VERSION "created by canmatrix"

NS_ :

BS_:

BU_:

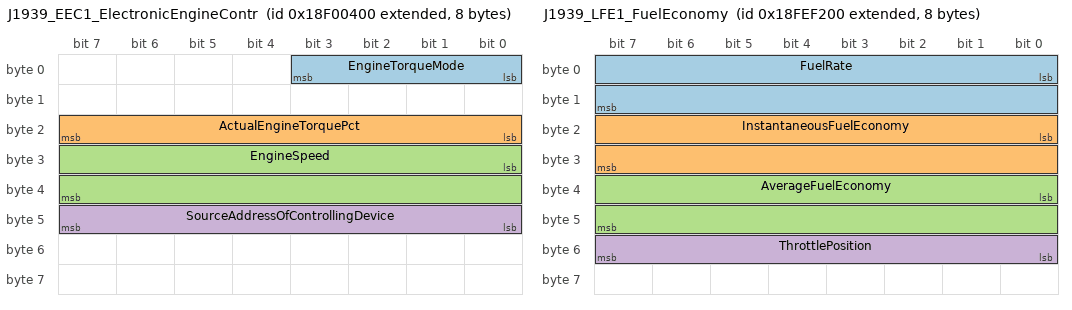
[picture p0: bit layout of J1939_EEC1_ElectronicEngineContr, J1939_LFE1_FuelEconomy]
BO_ 2565866496 J1939_EEC1_ElectronicEngineContr: 8 Vector__XXX
 SG_ EngineTorqueMode : 0|4@1+ (1,0) [0|15] "" Vector__XXX
 SG_ ActualEngineTorquePct : 16|8@1+ (1,-125) [-125|130] "%" Vector__XXX
 SG_ EngineSpeed : 24|16@1+ (0.125,0) [0|8191.875] "rpm" Vector__XXX
 SG_ SourceAddressOfControllingDevice : 40|8@1+ (1,0) [0|255] "" Vector__XXX

BO_ 2566844928 J1939_LFE1_FuelEconomy: 8 Vector__XXX
 SG_ FuelRate : 0|16@1+ (0.05,0) [0|3276.75] "L/h" Vector__XXX
 SG_ InstantaneousFuelEconomy : 16|16@1+ (0.001953,0) [0|127.989855] "km/L" Vector__XXX
 SG_ AverageFuelEconomy : 32|16@1+ (0.001953,0) [0|127.989855] "km/L" Vector__XXX
 SG_ ThrottlePosition : 48|8@1+ (0.4,0) [0|102] "%" Vector__XXX

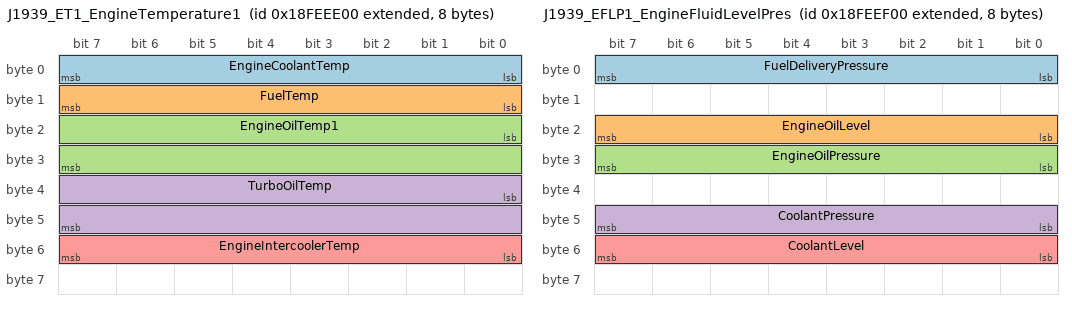
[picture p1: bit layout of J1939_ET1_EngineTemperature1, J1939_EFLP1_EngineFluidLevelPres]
BO_ 2566843904 J1939_ET1_EngineTemperature1: 8 Vector__XXX
 SG_ EngineCoolantTemp : 0|8@1+ (1,-40) [-40|215] "°C" Vector__XXX
 SG_ FuelTemp : 8|8@1+ (1,-40) [-40|215] "°C" Vector__XXX
 SG_ EngineOilTemp1 : 16|16@1+ (0.03125,-273) [-273|1774.96875] "°C" Vector__XXX
 SG_ TurboOilTemp : 32|16@1+ (0.03125,-273) [-273|1774.96875] "°C" Vector__XXX
 SG_ EngineIntercoolerTemp : 48|8@1+ (1,-40) [-40|215] "°C" Vector__XXX

BO_ 2566844160 J1939_EFLP1_EngineFluidLevelPres: 8 Vector__XXX
 SG_ FuelDeliveryPressure : 0|8@1+ (4,0) [0|1020] "kPa" Vector__XXX
 SG_ EngineOilLevel : 16|8@1+ (0.4,0) [0|102] "%" Vector__XXX
 SG_ EngineOilPressure : 24|8@1+ (4,0) [0|1020] "kPa" Vector__XXX
 SG_ CoolantPressure : 40|8@1+ (2,0) [0|510] "kPa" Vector__XXX
 SG_ CoolantLevel : 48|8@1+ (0.4,0) [0|102] "%" Vector__XXX

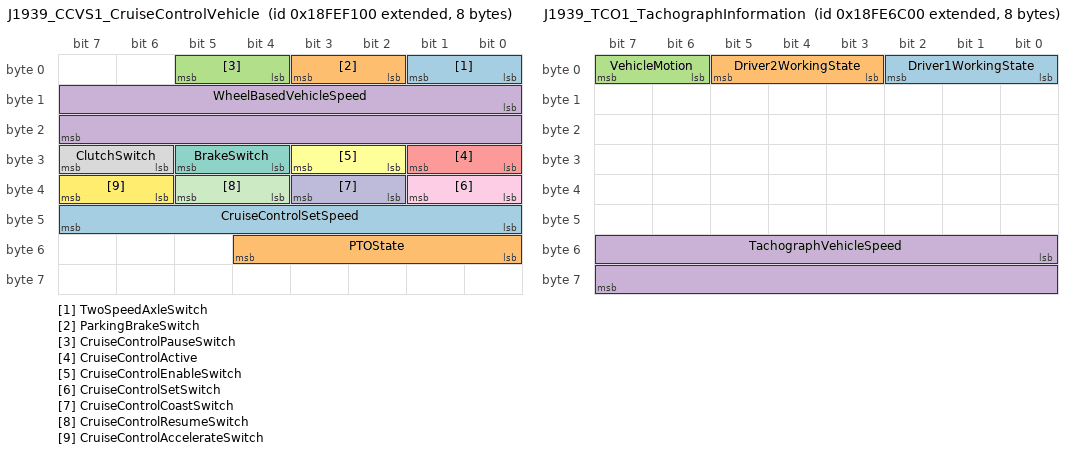
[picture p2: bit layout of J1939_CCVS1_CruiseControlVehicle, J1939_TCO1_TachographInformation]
BO_ 2566844672 J1939_CCVS1_CruiseControlVehicle: 8 Vector__XXX
 SG_ TwoSpeedAxleSwitch : 0|2@1+ (1,0) [0|3] "" Vector__XXX
 SG_ ParkingBrakeSwitch : 2|2@1+ (1,0) [0|3] "" Vector__XXX
 SG_ CruiseControlPauseSwitch : 4|2@1+ (1,0) [0|3] "" Vector__XXX
 SG_ WheelBasedVehicleSpeed : 8|16@1+ (0.003906,0) [0|255.97971] "km/h" Vector__XXX
 SG_ CruiseControlActive : 24|2@1+ (1,0) [0|3] "" Vector__XXX
 SG_ CruiseControlEnableSwitch : 26|2@1+ (1,0) [0|3] "" Vector__XXX
 SG_ BrakeSwitch : 28|2@1+ (1,0) [0|3] "" Vector__XXX
 SG_ ClutchSwitch : 30|2@1+ (1,0) [0|3] "" Vector__XXX
 SG_ CruiseControlSetSwitch : 32|2@1+ (1,0) [0|3] "" Vector__XXX
 SG_ CruiseControlCoastSwitch : 34|2@1+ (1,0) [0|3] "" Vector__XXX
 SG_ CruiseControlResumeSwitch : 36|2@1+ (1,0) [0|3] "" Vector__XXX
 SG_ CruiseControlAccelerateSwitch : 38|2@1+ (1,0) [0|3] "" Vector__XXX
 SG_ CruiseControlSetSpeed : 40|8@1+ (1,0) [0|255] "km/h" Vector__XXX
 SG_ PTOState : 48|5@1+ (1,0) [0|31] "" Vector__XXX

BO_ 2566810624 J1939_TCO1_TachographInformation: 8 Vector__XXX
 SG_ Driver1WorkingState : 0|3@1+ (1,0) [0|7] "" Vector__XXX
 SG_ Driver2WorkingState : 3|3@1+ (1,0) [0|7] "" Vector__XXX
 SG_ VehicleMotion : 6|2@1+ (1,0) [0|3] "" Vector__XXX
 SG_ TachographVehicleSpeed : 48|16@1+ (0.003906,0) [0|255.97971] "km/h" Vector__XXX

BO_ 2566841600 J1939_HOURS_EngineHours: 8 Vector__XXX
 SG_ EngineTotalHoursOfOperation : 0|32@1+ (0.05,0) [0|214748364.75] "h" Vector__XXX
 SG_ EngineTotalRevolutions : 32|32@1+ (1000,0) [0|4294967295000] "r" Vector__XXX

BO_ 2566843392 J1939_VI_VehicleIdentification: 8 Vector__XXX
 SG_ VIN_Char01 : 0|8@1+ (1,0) [0|255] "" Vector__XXX

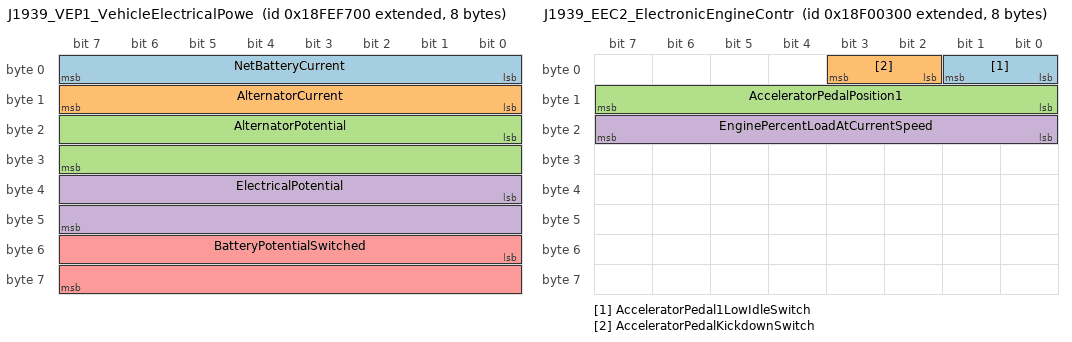
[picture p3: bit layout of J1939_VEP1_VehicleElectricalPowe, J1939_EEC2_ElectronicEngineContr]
BO_ 2566846208 J1939_VEP1_VehicleElectricalPowe: 8 Vector__XXX
 SG_ NetBatteryCurrent : 0|8@1+ (1,-125) [-125|130] "A" Vector__XXX
 SG_ AlternatorCurrent : 8|8@1+ (1,0) [0|255] "A" Vector__XXX
 SG_ AlternatorPotential : 16|16@1+ (0.05,0) [0|3276.75] "V" Vector__XXX
 SG_ ElectricalPotential : 32|16@1+ (0.05,0) [0|3276.75] "V" Vector__XXX
 SG_ BatteryPotentialSwitched : 48|16@1+ (0.05,0) [0|3276.75] "V" Vector__XXX

BO_ 2566749184 J1939_DEF_DieselExhaustFluidConc: 8 Vector__XXX
 SG_ DEFTankLevel : 0|8@1+ (0.4,0) [0|102] "%" Vector__XXX
 SG_ DEFTankTemperature : 8|8@1+ (1,-40) [-40|215] "°C" Vector__XXX

BO_ 2566841088 J1939_EC1_EngineConfiguration1: 8 Vector__XXX
 SG_ EngineSpeedAtIdle : 0|16@1+ (0.125,0) [0|8191.875] "rpm" Vector__XXX
 SG_ EngineSpeedAtMaxIdlePoint1 : 24|16@1+ (0.125,0) [0|8191.875] "rpm" Vector__XXX

BO_ 2566840064 J1939_EEC3_ElectronicEngineContr: 8 Vector__XXX
 SG_ EngineDemandPercentTorque : 56|8@1+ (1,-125) [-125|130] "%" Vector__XXX

BO_ 2565866240 J1939_EEC2_ElectronicEngineContr: 8 Vector__XXX
 SG_ AcceleratorPedal1LowIdleSwitch : 0|2@1+ (1,0) [0|3] "" Vector__XXX
 SG_ AcceleratorPedalKickdownSwitch : 2|2@1+ (1,0) [0|3] "" Vector__XXX
 SG_ AcceleratorPedalPosition1 : 8|8@1+ (0.4,0) [0|102] "%" Vector__XXX
 SG_ EnginePercentLoadAtCurrentSpeed : 16|8@1+ (1,0) [0|255] "%" Vector__XXX

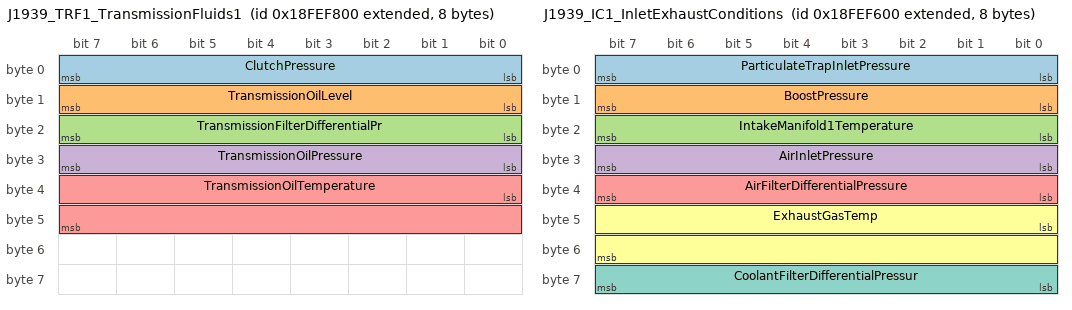
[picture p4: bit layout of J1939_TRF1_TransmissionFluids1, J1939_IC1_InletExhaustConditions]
BO_ 2566846464 J1939_TRF1_TransmissionFluids1: 8 Vector__XXX
 SG_ ClutchPressure : 0|8@1+ (16,0) [0|4080] "kPa" Vector__XXX
 SG_ TransmissionOilLevel : 8|8@1+ (0.4,0) [0|102] "%" Vector__XXX
 SG_ TransmissionFilterDifferentialPr : 16|8@1+ (2,0) [0|510] "kPa" Vector__XXX
 SG_ TransmissionOilPressure : 24|8@1+ (16,0) [0|4080] "kPa" Vector__XXX
 SG_ TransmissionOilTemperature : 32|16@1+ (0.03125,-273) [-273|1774.96875] "°C" Vector__XXX

BO_ 2566845952 J1939_IC1_InletExhaustConditions: 8 Vector__XXX
 SG_ ParticulateTrapInletPressure : 0|8@1+ (0.5,0) [0|127.5] "kPa" Vector__XXX
 SG_ BoostPressure : 8|8@1+ (2,0) [0|510] "kPa" Vector__XXX
 SG_ IntakeManifold1Temperature : 16|8@1+ (1,-40) [-40|215] "°C" Vector__XXX
 SG_ AirInletPressure : 24|8@1+ (2,0) [0|510] "kPa" Vector__XXX
 SG_ AirFilterDifferentialPressure : 32|8@1+ (0.05,0) [0|12.75] "kPa" Vector__XXX
 SG_ ExhaustGasTemp : 40|16@1+ (0.03125,-273) [-273|1774.96875] "°C" Vector__XXX
 SG_ CoolantFilterDifferentialPressur : 56|8@1+ (0.5,0) [0|127.5] "kPa" Vector__XXX

BO_ 2566697472 J1939_FFE_FuelEconomyExtended: 8 Vector__XXX
 SG_ EngineTripFuel : 0|32@1+ (0.5,0) [0|2147483647.5] "L" Vector__XXX
 SG_ EngineTotalFuelUsed : 32|32@1+ (0.5,0) [0|2147483647.5] "L" Vector__XXX

BO_ 2566832384 J1939_HRVD_HighResolutionVehicle: 8 Vector__XXX
 SG_ HighResolutionTotalVehicleDistan : 0|32@1+ (5,0) [0|21474836475] "m" Vector__XXX
 SG_ HighResolutionTripDistance : 32|32@1+ (5,0) [0|21474836475] "m" Vector__XXX

CM_ BO_ 2565866496  "Engine speed, torque mode, demand torque. Source: Wikipedia SAE J1939 PGN list (en.wikipedia.org/wiki/SAE_J1939)";
CM_ BO_ 2566844928  "Fuel rate + instantaneous + average fuel economy. Source: Wikipedia SAE J1939 PGN list (en.wikipedia.org/wiki/SAE_J1939)";
CM_ BO_ 2566843904  "Coolant + fuel + engine oil + intercooler temperatures. Source: Wikipedia SAE J1939 PGN list (en.wikipedia.org/wiki/SAE_J1939)";
CM_ BO_ 2566844160  "Oil pressure/level + coolant pressure/level + fuel delivery pressure. Source: Wikipedia SAE J1939 PGN list (en.wikipedia.org/wiki/SAE_J1939)";
CM_ BO_ 2566844672  "Vehicle speed + cruise control state + brake/clutch/parking switches. Source: Wikipedia SAE J1939 PGN list (en.wikipedia.org/wiki/SAE_J1939)";
CM_ BO_ 2566810624  "Tachograph + driver state (mostly for heavy-truck FMS). Source: Wikipedia SAE J1939 PGN list (en.wikipedia.org/wiki/SAE_J1939)";
CM_ BO_ 2566841600  "Engine total hours of operation. Source: Wikipedia SAE J1939 PGN list (en.wikipedia.org/wiki/SAE_J1939)";
CM_ BO_ 2566843392  "Vehicle Identification Number (VIN). Source: Wikipedia SAE J1939 PGN list (en.wikipedia.org/wiki/SAE_J1939)";
CM_ BO_ 2566846208  "Battery + alternator + engine starter electrical state. Source: Wikipedia SAE J1939 PGN list (en.wikipedia.org/wiki/SAE_J1939)";
CM_ BO_ 2566749184  "DEF (urea) tank level + temperature + concentration. Source: Wikipedia SAE J1939 PGN list (en.wikipedia.org/wiki/SAE_J1939)";
CM_ BO_ 2566841088  "Engine configuration data — displacement, speed limits, fuel type. Source: Wikipedia SAE J1939 PGN list (en.wikipedia.org/wiki/SAE_J1939)";
CM_ BO_ 2566840064  "Engine demand percent torque + nominal friction torque. Source: Wikipedia SAE J1939 PGN list (en.wikipedia.org/wiki/SAE_J1939)";
CM_ BO_ 2565866240  "Accelerator pedal + percent load. Source: Wikipedia SAE J1939 PGN list (en.wikipedia.org/wiki/SAE_J1939)";
CM_ BO_ 2566846464  "Transmission oil + clutch pressure. Source: Wikipedia SAE J1939 PGN list (en.wikipedia.org/wiki/SAE_J1939)";
CM_ BO_ 2566845952  "Boost + intake air temp + air filter differential pressure. Source: Wikipedia SAE J1939 PGN list (en.wikipedia.org/wiki/SAE_J1939)";
CM_ BO_ 2566697472  "Trip fuel + total fuel + trip distance. Source: Wikipedia SAE J1939 PGN list (en.wikipedia.org/wiki/SAE_J1939)";
CM_ BO_ 2566832384  "High-resolution vehicle distance (HRVD per SAE J1939-71). Source: Wikipedia SAE J1939 PGN list (en.wikipedia.org/wiki/SAE_J1939)";

CM_ SG_ 2565866496 EngineTorqueMode "Per-signal source: Wikipedia SAE J1939 PGN list (en.wikipedia.org/wiki/SAE_J1939)";
CM_ SG_ 2565866496 ActualEngineTorquePct "Actual engine percent torque";
CM_ SG_ 2565866496 EngineSpeed "Per-signal source: Wikipedia SAE J1939 PGN list (en.wikipedia.org/wiki/SAE_J1939)";
CM_ SG_ 2565866496 SourceAddressOfControllingDevice "Source address of the device commanding engine torque";
CM_ SG_ 2566844928 FuelRate "Per-signal source: Wikipedia SAE J1939 PGN list (en.wikipedia.org/wiki/SAE_J1939)";
CM_ SG_ 2566844928 InstantaneousFuelEconomy "Per-signal source: Wikipedia SAE J1939 PGN list (en.wikipedia.org/wiki/SAE_J1939)";
CM_ SG_ 2566844928 AverageFuelEconomy "Per-signal source: Wikipedia SAE J1939 PGN list (en.wikipedia.org/wiki/SAE_J1939)";
CM_ SG_ 2566844928 ThrottlePosition "Per-signal source: Wikipedia SAE J1939 PGN list (en.wikipedia.org/wiki/SAE_J1939)";
CM_ SG_ 2566843904 EngineCoolantTemp "Per-signal source: Wikipedia SAE J1939 PGN list (en.wikipedia.org/wiki/SAE_J1939)";
CM_ SG_ 2566843904 FuelTemp "Per-signal source: Wikipedia SAE J1939 PGN list (en.wikipedia.org/wiki/SAE_J1939)";
CM_ SG_ 2566843904 EngineOilTemp1 "Per-signal source: Wikipedia SAE J1939 PGN list (en.wikipedia.org/wiki/SAE_J1939)";
CM_ SG_ 2566843904 TurboOilTemp "Per-signal source: Wikipedia SAE J1939 PGN list (en.wikipedia.org/wiki/SAE_J1939)";
CM_ SG_ 2566843904 EngineIntercoolerTemp "Per-signal source: Wikipedia SAE J1939 PGN list (en.wikipedia.org/wiki/SAE_J1939)";
CM_ SG_ 2566844160 FuelDeliveryPressure "Per-signal source: Wikipedia SAE J1939 PGN list (en.wikipedia.org/wiki/SAE_J1939)";
CM_ SG_ 2566844160 EngineOilLevel "Per-signal source: Wikipedia SAE J1939 PGN list (en.wikipedia.org/wiki/SAE_J1939)";
CM_ SG_ 2566844160 EngineOilPressure "Per-signal source: Wikipedia SAE J1939 PGN list (en.wikipedia.org/wiki/SAE_J1939)";
CM_ SG_ 2566844160 CoolantPressure "Per-signal source: Wikipedia SAE J1939 PGN list (en.wikipedia.org/wiki/SAE_J1939)";
CM_ SG_ 2566844160 CoolantLevel "Per-signal source: Wikipedia SAE J1939 PGN list (en.wikipedia.org/wiki/SAE_J1939)";
CM_ SG_ 2566844672 TwoSpeedAxleSwitch "Per-signal source: Wikipedia SAE J1939 PGN list (en.wikipedia.org/wiki/SAE_J1939)";
CM_ SG_ 2566844672 ParkingBrakeSwitch "Per-signal source: Wikipedia SAE J1939 PGN list (en.wikipedia.org/wiki/SAE_J1939)";
CM_ SG_ 2566844672 CruiseControlPauseSwitch "Per-signal source: Wikipedia SAE J1939 PGN list (en.wikipedia.org/wiki/SAE_J1939)";
CM_ SG_ 2566844672 WheelBasedVehicleSpeed "Per-signal source: Wikipedia SAE J1939 PGN list (en.wikipedia.org/wiki/SAE_J1939)";
CM_ SG_ 2566844672 CruiseControlActive "Per-signal source: Wikipedia SAE J1939 PGN list (en.wikipedia.org/wiki/SAE_J1939)";
CM_ SG_ 2566844672 CruiseControlEnableSwitch "Per-signal source: Wikipedia SAE J1939 PGN list (en.wikipedia.org/wiki/SAE_J1939)";
CM_ SG_ 2566844672 BrakeSwitch "Per-signal source: Wikipedia SAE J1939 PGN list (en.wikipedia.org/wiki/SAE_J1939)";
CM_ SG_ 2566844672 ClutchSwitch "Per-signal source: Wikipedia SAE J1939 PGN list (en.wikipedia.org/wiki/SAE_J1939)";
CM_ SG_ 2566844672 CruiseControlSetSwitch "Per-signal source: Wikipedia SAE J1939 PGN list (en.wikipedia.org/wiki/SAE_J1939)";
CM_ SG_ 2566844672 CruiseControlCoastSwitch "Per-signal source: Wikipedia SAE J1939 PGN list (en.wikipedia.org/wiki/SAE_J1939)";
CM_ SG_ 2566844672 CruiseControlResumeSwitch "Per-signal source: Wikipedia SAE J1939 PGN list (en.wikipedia.org/wiki/SAE_J1939)";
CM_ SG_ 2566844672 CruiseControlAccelerateSwitch "Per-signal source: Wikipedia SAE J1939 PGN list (en.wikipedia.org/wiki/SAE_J1939)";
CM_ SG_ 2566844672 CruiseControlSetSpeed "Per-signal source: Wikipedia SAE J1939 PGN list (en.wikipedia.org/wiki/SAE_J1939)";
CM_ SG_ 2566844672 PTOState "Per-signal source: Wikipedia SAE J1939 PGN list (en.wikipedia.org/wiki/SAE_J1939)";
CM_ SG_ 2566810624 Driver1WorkingState "Per-signal source: Wikipedia SAE J1939 PGN list (en.wikipedia.org/wiki/SAE_J1939)";
CM_ SG_ 2566810624 Driver2WorkingState "Per-signal source: Wikipedia SAE J1939 PGN list (en.wikipedia.org/wiki/SAE_J1939)";
CM_ SG_ 2566810624 VehicleMotion "Per-signal source: Wikipedia SAE J1939 PGN list (en.wikipedia.org/wiki/SAE_J1939)";
CM_ SG_ 2566810624 TachographVehicleSpeed "Per-signal source: Wikipedia SAE J1939 PGN list (en.wikipedia.org/wiki/SAE_J1939)";
CM_ SG_ 2566841600 EngineTotalHoursOfOperation "Per-signal source: Wikipedia SAE J1939 PGN list (en.wikipedia.org/wiki/SAE_J1939)";
CM_ SG_ 2566841600 EngineTotalRevolutions "Per-signal source: Wikipedia SAE J1939 PGN list (en.wikipedia.org/wiki/SAE_J1939)";
CM_ SG_ 2566843392 VIN_Char01 "ASCII byte 0 of VIN; full VIN spans multipacket";
CM_ SG_ 2566846208 NetBatteryCurrent "Per-signal source: Wikipedia SAE J1939 PGN list (en.wikipedia.org/wiki/SAE_J1939)";
CM_ SG_ 2566846208 AlternatorCurrent "Per-signal source: Wikipedia SAE J1939 PGN list (en.wikipedia.org/wiki/SAE_J1939)";
CM_ SG_ 2566846208 AlternatorPotential "Per-signal source: Wikipedia SAE J1939 PGN list (en.wikipedia.org/wiki/SAE_J1939)";
CM_ SG_ 2566846208 ElectricalPotential "Per-signal source: Wikipedia SAE J1939 PGN list (en.wikipedia.org/wiki/SAE_J1939)";
CM_ SG_ 2566846208 BatteryPotentialSwitched "Per-signal source: Wikipedia SAE J1939 PGN list (en.wikipedia.org/wiki/SAE_J1939)";
CM_ SG_ 2566749184 DEFTankLevel "Per-signal source: Wikipedia SAE J1939 PGN list (en.wikipedia.org/wiki/SAE_J1939)";
CM_ SG_ 2566749184 DEFTankTemperature "Per-signal source: Wikipedia SAE J1939 PGN list (en.wikipedia.org/wiki/SAE_J1939)";
CM_ SG_ 2566841088 EngineSpeedAtIdle "Per-signal source: Wikipedia SAE J1939 PGN list (en.wikipedia.org/wiki/SAE_J1939)";
CM_ SG_ 2566841088 EngineSpeedAtMaxIdlePoint1 "Per-signal source: Wikipedia SAE J1939 PGN list (en.wikipedia.org/wiki/SAE_J1939)";
CM_ SG_ 2566840064 EngineDemandPercentTorque "Per-signal source: Wikipedia SAE J1939 PGN list (en.wikipedia.org/wiki/SAE_J1939)";
CM_ SG_ 2565866240 AcceleratorPedal1LowIdleSwitch "Per-signal source: Wikipedia SAE J1939 PGN list (en.wikipedia.org/wiki/SAE_J1939)";
CM_ SG_ 2565866240 AcceleratorPedalKickdownSwitch "Per-signal source: Wikipedia SAE J1939 PGN list (en.wikipedia.org/wiki/SAE_J1939)";
CM_ SG_ 2565866240 AcceleratorPedalPosition1 "Per-signal source: Wikipedia SAE J1939 PGN list (en.wikipedia.org/wiki/SAE_J1939)";
CM_ SG_ 2565866240 EnginePercentLoadAtCurrentSpeed "Per-signal source: Wikipedia SAE J1939 PGN list (en.wikipedia.org/wiki/SAE_J1939)";
CM_ SG_ 2566846464 ClutchPressure "Per-signal source: Wikipedia SAE J1939 PGN list (en.wikipedia.org/wiki/SAE_J1939)";
CM_ SG_ 2566846464 TransmissionOilLevel "Per-signal source: Wikipedia SAE J1939 PGN list (en.wikipedia.org/wiki/SAE_J1939)";
CM_ SG_ 2566846464 TransmissionFilterDifferentialPr "Per-signal source: Wikipedia SAE J1939 PGN list (en.wikipedia.org/wiki/SAE_J1939)";
CM_ SG_ 2566846464 TransmissionOilPressure "Per-signal source: Wikipedia SAE J1939 PGN list (en.wikipedia.org/wiki/SAE_J1939)";
CM_ SG_ 2566846464 TransmissionOilTemperature "Per-signal source: Wikipedia SAE J1939 PGN list (en.wikipedia.org/wiki/SAE_J1939)";
CM_ SG_ 2566845952 ParticulateTrapInletPressure "Per-signal source: Wikipedia SAE J1939 PGN list (en.wikipedia.org/wiki/SAE_J1939)";
CM_ SG_ 2566845952 BoostPressure "Per-signal source: Wikipedia SAE J1939 PGN list (en.wikipedia.org/wiki/SAE_J1939)";
CM_ SG_ 2566845952 IntakeManifold1Temperature "Per-signal source: Wikipedia SAE J1939 PGN list (en.wikipedia.org/wiki/SAE_J1939)";
CM_ SG_ 2566845952 AirInletPressure "Per-signal source: Wikipedia SAE J1939 PGN list (en.wikipedia.org/wiki/SAE_J1939)";
CM_ SG_ 2566845952 AirFilterDifferentialPressure "Per-signal source: Wikipedia SAE J1939 PGN list (en.wikipedia.org/wiki/SAE_J1939)";
CM_ SG_ 2566845952 ExhaustGasTemp "Per-signal source: Wikipedia SAE J1939 PGN list (en.wikipedia.org/wiki/SAE_J1939)";
CM_ SG_ 2566845952 CoolantFilterDifferentialPressur "Per-signal source: Wikipedia SAE J1939 PGN list (en.wikipedia.org/wiki/SAE_J1939)";
CM_ SG_ 2566697472 EngineTripFuel "Per-signal source: Wikipedia SAE J1939 PGN list (en.wikipedia.org/wiki/SAE_J1939)";
CM_ SG_ 2566697472 EngineTotalFuelUsed "Per-signal source: Wikipedia SAE J1939 PGN list (en.wikipedia.org/wiki/SAE_J1939)";
CM_ SG_ 2566832384 HighResolutionTotalVehicleDistan "Per-signal source: Wikipedia SAE J1939 PGN list (en.wikipedia.org/wiki/SAE_J1939)";
CM_ SG_ 2566832384 HighResolutionTripDistance "Per-signal source: Wikipedia SAE J1939 PGN list (en.wikipedia.org/wiki/SAE_J1939)";

BA_DEF_ BO_ "SystemMessageLongSymbol" STRING;
BA_DEF_ SG_ "GenSigStartValue" FLOAT 0 100000000000;
BA_DEF_ SG_ "SystemSignalLongSymbol" STRING;

BA_ "SystemMessageLongSymbol" BO_ 2565866496 "J1939_EEC1_ElectronicEngineController1";
BA_ "SystemMessageLongSymbol" BO_ 2566844160 "J1939_EFLP1_EngineFluidLevelPressure1";
BA_ "SystemMessageLongSymbol" BO_ 2566844672 "J1939_CCVS1_CruiseControlVehicleSpeed1";
BA_ "SystemMessageLongSymbol" BO_ 2566846208 "J1939_VEP1_VehicleElectricalPower1";
BA_ "SystemMessageLongSymbol" BO_ 2566749184 "J1939_DEF_DieselExhaustFluidConcentration";
BA_ "SystemMessageLongSymbol" BO_ 2566840064 "J1939_EEC3_ElectronicEngineController3";
BA_ "SystemMessageLongSymbol" BO_ 2565866240 "J1939_EEC2_ElectronicEngineController2";
BA_ "SystemMessageLongSymbol" BO_ 2566845952 "J1939_IC1_InletExhaustConditions1";
BA_ "SystemMessageLongSymbol" BO_ 2566832384 "J1939_HRVD_HighResolutionVehicleDistance";

BA_ "SystemSignalLongSymbol" SG_ 2147548920 TransmissionFilterDifferentialPr "TransmissionFilterDifferentialPressure";
BA_ "SystemSignalLongSymbol" SG_ 2147548918 CoolantFilterDifferentialPressur "CoolantFilterDifferentialPressure";
BA_ "SystemSignalLongSymbol" SG_ 2147548865 HighResolutionTotalVehicleDistan "HighResolutionTotalVehicleDistance";

VAL_ 2565866496 EngineTorqueMode 0 "LowIdleGovernor" 1 "AcceleratorPedal" 2 "CruiseControl" 3 "PTOGovernor" 4 "RoadSpeedGovernor" 5 "ASRControl" 6 "TransmissionControl" 7 "ABSControl" 8 "TorqueLimiting" 9 "HighSpeedGovernor" 10 "BrakingSystem" 11 "RemoteAccelerator" 14 "Other" 15 "NotAvailable";

VERSION "created by canmatrix"

NS_ :

BS_:

BU_:

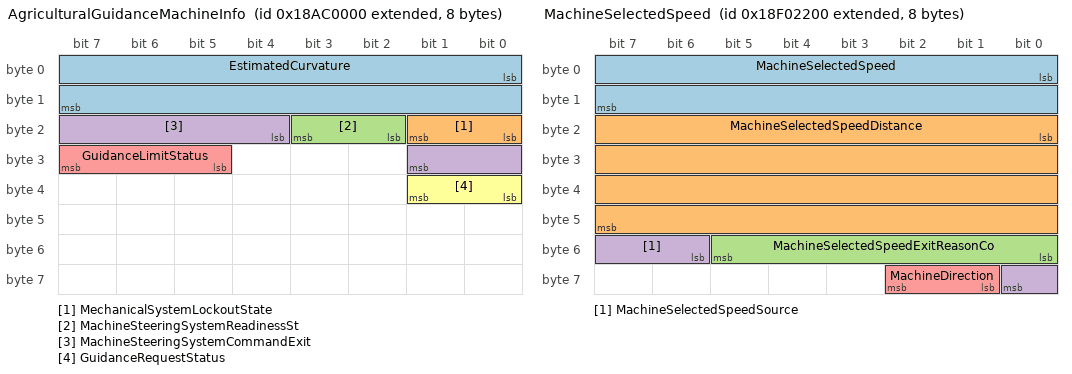
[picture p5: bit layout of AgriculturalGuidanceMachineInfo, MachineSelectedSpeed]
BO_ 2561409024 AgriculturalGuidanceMachineInfo: 8 Vector__XXX
 SG_ EstimatedCurvature : 0|16@1+ (0.25,-8032) [-8032|8351.75] "1/km" Vector__XXX
 SG_ MechanicalSystemLockoutState : 16|2@1+ (1,0) [0|3] "" Vector__XXX
 SG_ MachineSteeringSystemReadinessSt : 18|2@1+ (1,0) [0|3] "" Vector__XXX
 SG_ MachineSteeringSystemCommandExit : 20|6@1+ (1,0) [0|63] "" Vector__XXX
 SG_ GuidanceLimitStatus : 29|3@1+ (1,0) [0|7] "" Vector__XXX
 SG_ GuidanceRequestStatus : 32|2@1+ (1,0) [0|3] "" Vector__XXX

BO_ 2561474560 AgriculturalGuidanceSystemComman: 8 Vector__XXX
 SG_ CurvatureCommand : 0|16@1+ (0.25,-8032) [-8032|8351.75] "1/km" Vector__XXX
 SG_ CurvatureCommandStatus : 16|2@1+ (1,0) [0|3] "" Vector__XXX

BO_ 2562916352 DiagnosticMessage22: 8 Vector__XXX
 SG_ DiagnosticMessage22_RawPayload : 0|64@1+ (1,0) [0|18446744073709551615] "" Vector__XXX

BO_ 2563178496 ExtendedTransportProtocolDataTra: 8 Vector__XXX
 SG_ ExtendedTransportProtocolDataTra : 0|64@1+ (1,0) [0|18446744073709551615] "" Vector__XXX

BO_ 2563244032 ExtendedTransportProtocolConnect: 8 Vector__XXX
 SG_ ExtendedTransportProtocolConnect : 0|64@1+ (1,0) [0|18446744073709551615] "" Vector__XXX

BO_ 2563440640 ProcessData: 8 Vector__XXX
 SG_ ProcessData_RawPayload : 0|64@1+ (1,0) [0|18446744073709551615] "" Vector__XXX

BO_ 2563506176 RequestForRepetitionRate: 8 Vector__XXX
 SG_ RequestForRepetitionRate_RawPayl : 0|64@1+ (1,0) [0|18446744073709551615] "" Vector__XXX

BO_ 2564751360 DiagnosticMessage13: 8 Vector__XXX
 SG_ DiagnosticMessage13_RawPayload : 0|64@1+ (1,0) [0|18446744073709551615] "" Vector__XXX

BO_ 2565210112 VirtualTerminalToECU: 8 Vector__XXX
 SG_ VirtualTerminalToECU_RawPayload : 0|64@1+ (1,0) [0|18446744073709551615] "" Vector__XXX

BO_ 2565275648 ECUtoVirtualTerminal: 8 Vector__XXX
 SG_ ECUtoVirtualTerminal_RawPayload : 0|64@1+ (1,0) [0|18446744073709551615] "" Vector__XXX

BO_ 2565341184 Acknowledge: 8 Vector__XXX
 SG_ Acknowledge_RawPayload : 0|64@1+ (1,0) [0|18446744073709551615] "" Vector__XXX

BO_ 2565472256 ParameterGroupNumberRequest: 8 Vector__XXX
 SG_ ParameterGroupNumberRequest_RawP : 0|64@1+ (1,0) [0|18446744073709551615] "" Vector__XXX

BO_ 2565537792 TransportProtocolDataTransfer: 8 Vector__XXX
 SG_ TransportProtocolDataTransfer_Ra : 0|64@1+ (1,0) [0|18446744073709551615] "" Vector__XXX

BO_ 2565603328 TransportProtocolConnectionManag: 8 Vector__XXX
 SG_ TransportProtocolConnectionManag : 0|64@1+ (1,0) [0|18446744073709551615] "" Vector__XXX

BO_ 2565734400 AddressClaim: 8 Vector__XXX
 SG_ AddressClaim_RawPayload : 0|64@1+ (1,0) [0|18446744073709551615] "" Vector__XXX

BO_ 2565874176 MachineSelectedSpeed: 8 Vector__XXX
 SG_ MachineSelectedSpeed : 0|16@1+ (0.001,0) [0|65.535] "m/s" Vector__XXX
 SG_ MachineSelectedSpeedDistance : 16|32@1+ (1,0) [0|4294967295] "m" Vector__XXX
 SG_ MachineSelectedSpeedExitReasonCo : 48|6@1+ (1,0) [0|63] "" Vector__XXX
 SG_ MachineSelectedSpeedSource : 54|3@1+ (1,0) [0|7] "" Vector__XXX
 SG_ MachineDirection : 57|2@1+ (1,0) [0|3] "" Vector__XXX

BO_ 2565923840 HeartbeatMessage: 8 Vector__XXX
 SG_ HeartbeatSequenceCounter : 0|8@1+ (1,0) [0|255] "" Vector__XXX

BO_ 2566688000 ProductIdentification: 8 Vector__XXX
 SG_ ProductIdentification_RawPayload : 0|64@1+ (1,0) [0|18446744073709551615] "" Vector__XXX

BO_ 2566688256 ControlFunctionFunctionalities: 8 Vector__XXX
 SG_ ControlFunctionFunctionalities_R : 0|64@1+ (1,0) [0|18446744073709551615] "" Vector__XXX

BO_ 2566730240 DiagnosticProtocolIdentification: 8 Vector__XXX
 SG_ DiagnosticProtocolIdentification : 0|64@1+ (1,0) [0|18446744073709551615] "" Vector__XXX

BO_ 2566734592 MachineSelectedSpeedCommand: 8 Vector__XXX
 SG_ MachineSelectedSpeedCommand_RawP : 0|64@1+ (1,0) [0|18446744073709551615] "" Vector__XXX

BO_ 2566786304 WorkingSetMaster: 8 Vector__XXX
 SG_ WorkingSetMaster_RawPayload : 0|64@1+ (1,0) [0|18446744073709551615] "" Vector__XXX

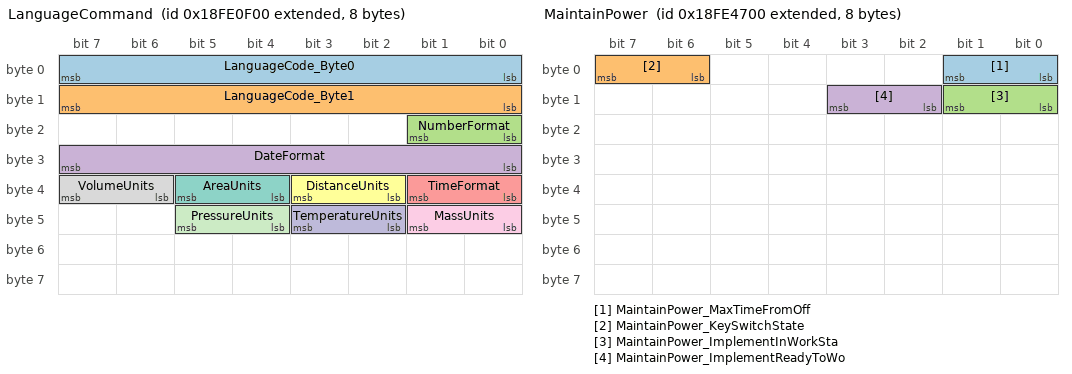
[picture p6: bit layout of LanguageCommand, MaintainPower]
BO_ 2566786816 LanguageCommand: 8 Vector__XXX
 SG_ LanguageCode_Byte0 : 0|8@1+ (1,0) [0|255] "" Vector__XXX
 SG_ LanguageCode_Byte1 : 8|8@1+ (1,0) [0|255] "" Vector__XXX
 SG_ NumberFormat : 16|2@1+ (1,0) [0|3] "" Vector__XXX
 SG_ DateFormat : 24|8@1+ (1,0) [0|255] "" Vector__XXX
 SG_ TimeFormat : 32|2@1+ (1,0) [0|3] "" Vector__XXX
 SG_ DistanceUnits : 34|2@1+ (1,0) [0|3] "" Vector__XXX
 SG_ AreaUnits : 36|2@1+ (1,0) [0|3] "" Vector__XXX
 SG_ VolumeUnits : 38|2@1+ (1,0) [0|3] "" Vector__XXX
 SG_ MassUnits : 40|2@1+ (1,0) [0|3] "" Vector__XXX
 SG_ TemperatureUnits : 42|2@1+ (1,0) [0|3] "" Vector__XXX
 SG_ PressureUnits : 44|2@1+ (1,0) [0|3] "" Vector__XXX

BO_ 2566801152 MaintainPower: 8 Vector__XXX
 SG_ MaintainPower_MaxTimeFromOff : 0|2@1+ (1,0) [0|3] "" Vector__XXX
 SG_ MaintainPower_KeySwitchState : 6|2@1+ (1,0) [0|3] "" Vector__XXX
 SG_ MaintainPower_ImplementInWorkSta : 8|2@1+ (1,0) [0|3] "" Vector__XXX
 SG_ MaintainPower_ImplementReadyToWo : 10|2@1+ (1,0) [0|3] "" Vector__XXX

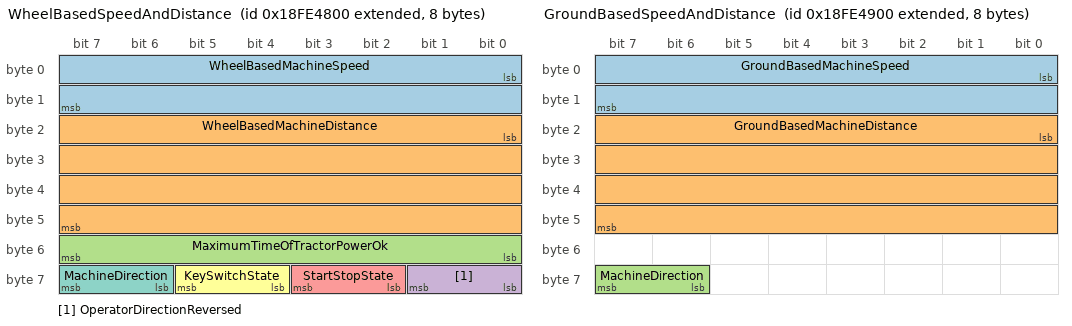
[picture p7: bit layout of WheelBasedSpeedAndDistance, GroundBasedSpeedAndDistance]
BO_ 2566801408 WheelBasedSpeedAndDistance: 8 Vector__XXX
 SG_ WheelBasedMachineSpeed : 0|16@1+ (0.001,0) [0|65.535] "m/s" Vector__XXX
 SG_ WheelBasedMachineDistance : 16|32@1+ (1,0) [0|4294967295] "m" Vector__XXX
 SG_ MaximumTimeOfTractorPowerOk : 48|8@1+ (1,0) [0|255] "minutes" Vector__XXX
 SG_ OperatorDirectionReversed : 56|2@1+ (1,0) [0|3] "" Vector__XXX
 SG_ StartStopState : 58|2@1+ (1,0) [0|3] "" Vector__XXX
 SG_ KeySwitchState : 60|2@1+ (1,0) [0|3] "" Vector__XXX
 SG_ MachineDirection : 62|2@1+ (1,0) [0|3] "" Vector__XXX

BO_ 2566801664 GroundBasedSpeedAndDistance: 8 Vector__XXX
 SG_ GroundBasedMachineSpeed : 0|16@1+ (0.001,0) [0|65.535] "m/s" Vector__XXX
 SG_ GroundBasedMachineDistance : 16|32@1+ (1,0) [0|4294967295] "m" Vector__XXX
 SG_ MachineDirection : 62|2@1+ (1,0) [0|3] "" Vector__XXX

BO_ 2566767872 ECUIdentificationInformation: 8 Vector__XXX
 SG_ ECUIdentificationInformation_Raw : 0|64@1+ (1,0) [0|18446744073709551615] "" Vector__XXX

BO_ 2566834688 DiagnosticMessage1: 8 Vector__XXX
 SG_ DiagnosticMessage1_RawPayload : 0|64@1+ (1,0) [0|18446744073709551615] "" Vector__XXX

BO_ 2566834944 DiagnosticMessage2: 8 Vector__XXX
 SG_ DiagnosticMessage2_RawPayload : 0|64@1+ (1,0) [0|18446744073709551615] "" Vector__XXX

BO_ 2566835200 DiagnosticMessage3: 8 Vector__XXX
 SG_ DiagnosticMessage3_RawPayload : 0|64@1+ (1,0) [0|18446744073709551615] "" Vector__XXX

BO_ 2566836992 DiagnosticMessage11: 8 Vector__XXX
 SG_ DiagnosticMessage11_RawPayload : 0|64@1+ (1,0) [0|18446744073709551615] "" Vector__XXX

BO_ 2564358144 DiagnosticMessage14: 8 Vector__XXX
 SG_ DiagnosticMessage14_RawPayload : 0|64@1+ (1,0) [0|18446744073709551615] "" Vector__XXX

BO_ 2564292608 DiagnosticMessage15: 8 Vector__XXX
 SG_ DiagnosticMessage15_RawPayload : 0|64@1+ (1,0) [0|18446744073709551615] "" Vector__XXX

BO_ 2564227072 DiagnosticMessage16: 8 Vector__XXX
 SG_ DiagnosticMessage16_RawPayload : 0|64@1+ (1,0) [0|18446744073709551615] "" Vector__XXX

BO_ 2566838272 CommandedAddress: 8 Vector__XXX
 SG_ CommandedAddress_RawPayload : 0|64@1+ (1,0) [0|18446744073709551615] "" Vector__XXX

BO_ 2566838784 SoftwareIdentification: 8 Vector__XXX
 SG_ SoftwareIdentification_RawPayloa : 0|64@1+ (1,0) [0|18446744073709551615] "" Vector__XXX

BO_ 2566717952 AllImplementsStopOperationsSwitc: 8 Vector__XXX
 SG_ AllImplementsStopOperationsSwitc : 0|64@1+ (1,0) [0|18446744073709551615] "" Vector__XXX

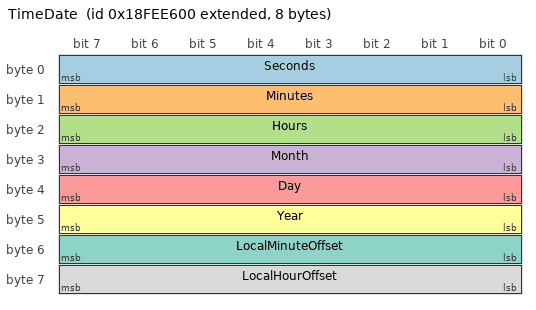
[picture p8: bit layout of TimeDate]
BO_ 2566841856 TimeDate: 8 Vector__XXX
 SG_ Seconds : 0|8@1+ (0.25,0) [0|63.75] "s" Vector__XXX
 SG_ Minutes : 8|8@1+ (1,0) [0|255] "min" Vector__XXX
 SG_ Hours : 16|8@1+ (1,0) [0|255] "h" Vector__XXX
 SG_ Month : 24|8@1+ (1,0) [0|255] "month" Vector__XXX
 SG_ Day : 32|8@1+ (0.25,0) [0|63.75] "day" Vector__XXX
 SG_ Year : 40|8@1+ (1,1985) [1985|2240] "year" Vector__XXX
 SG_ LocalMinuteOffset : 48|8@1+ (1,-125) [-125|130] "min" Vector__XXX
 SG_ LocalHourOffset : 56|8@1+ (1,-125) [-125|130] "h" Vector__XXX

BO_ 2566843136 ComponentIdentification: 8 Vector__XXX
 SG_ ComponentIdentification_RawPaylo : 0|64@1+ (1,0) [0|18446744073709551615] "" Vector__XXX

BO_ 2582712832 VesselHeading: 8 Vector__XXX
 SG_ VesselHeading_RawPayload : 0|64@1+ (1,0) [0|18446744073709551615] "" Vector__XXX

BO_ 2582713088 RateOfTurn: 8 Vector__XXX
 SG_ RateOfTurn_RawPayload : 0|64@1+ (1,0) [0|18446744073709551615] "" Vector__XXX

BO_ 2583167232 PositionRapidUpdate: 8 Vector__XXX
 SG_ PositionRapidUpdate_RawPayload : 0|64@1+ (1,0) [0|18446744073709551615] "" Vector__XXX

BO_ 2583167488 CourseOverGroundSpeedOverGroundR: 8 Vector__XXX
 SG_ CourseOverGroundSpeedOverGroundR : 0|64@1+ (1,0) [0|18446744073709551615] "" Vector__XXX

BO_ 2583167744 PositionDeltaHighPrecisionRapidU: 8 Vector__XXX
 SG_ PositionDeltaHighPrecisionRapidU : 0|64@1+ (1,0) [0|18446744073709551615] "" Vector__XXX

BO_ 2583168256 GNSSPositionData: 8 Vector__XXX
 SG_ GNSSPositionData_RawPayload : 0|64@1+ (1,0) [0|18446744073709551615] "" Vector__XXX

BO_ 2583172096 Datum: 8 Vector__XXX
 SG_ Datum_RawPayload : 0|64@1+ (1,0) [0|18446744073709551615] "" Vector__XXX

CM_ BO_ 2561409024  "Source: AgIsoStack++ can_general_parameter_group_numbers.hpp:19";
CM_ BO_ 2561474560  "Source: AgIsoStack++ can_general_parameter_group_numbers.hpp:20";
CM_ BO_ 2562916352  "Source: AgIsoStack++ can_general_parameter_group_numbers.hpp:21";
CM_ BO_ 2563178496  "Source: AgIsoStack++ can_general_parameter_group_numbers.hpp:22";
CM_ BO_ 2563244032  "Source: AgIsoStack++ can_general_parameter_group_numbers.hpp:23";
CM_ BO_ 2563440640  "Source: AgIsoStack++ can_general_parameter_group_numbers.hpp:24";
CM_ BO_ 2563506176  "Source: AgIsoStack++ can_general_parameter_group_numbers.hpp:25";
CM_ BO_ 2564751360  "Source: AgIsoStack++ can_general_parameter_group_numbers.hpp:26";
CM_ BO_ 2565210112  "Source: AgIsoStack++ can_general_parameter_group_numbers.hpp:27";
CM_ BO_ 2565275648  "Source: AgIsoStack++ can_general_parameter_group_numbers.hpp:28";
CM_ BO_ 2565341184  "Source: AgIsoStack++ can_general_parameter_group_numbers.hpp:29";
CM_ BO_ 2565472256  "Source: AgIsoStack++ can_general_parameter_group_numbers.hpp:30";
CM_ BO_ 2565537792  "Source: AgIsoStack++ can_general_parameter_group_numbers.hpp:31";
CM_ BO_ 2565603328  "Source: AgIsoStack++ can_general_parameter_group_numbers.hpp:32";
CM_ BO_ 2565734400  "Source: AgIsoStack++ can_general_parameter_group_numbers.hpp:33";
CM_ BO_ 2565874176  "Source: AgIsoStack++ can_general_parameter_group_numbers.hpp:35";
CM_ BO_ 2565923840  "Source: AgIsoStack++ can_general_parameter_group_numbers.hpp:36";
CM_ BO_ 2566688000  "Source: AgIsoStack++ can_general_parameter_group_numbers.hpp:37";
CM_ BO_ 2566688256  "Source: AgIsoStack++ can_general_parameter_group_numbers.hpp:38";
CM_ BO_ 2566730240  "Source: AgIsoStack++ can_general_parameter_group_numbers.hpp:39";
CM_ BO_ 2566734592  "Source: AgIsoStack++ can_general_parameter_group_numbers.hpp:40";
CM_ BO_ 2566786304  "Source: AgIsoStack++ can_general_parameter_group_numbers.hpp:41";
CM_ BO_ 2566786816  "Source: AgIsoStack++ can_general_parameter_group_numbers.hpp:42";
CM_ BO_ 2566801152  "Source: AgIsoStack++ can_general_parameter_group_numbers.hpp:43";
CM_ BO_ 2566801408  "Source: AgIsoStack++ can_general_parameter_group_numbers.hpp:44";
CM_ BO_ 2566801664  "Source: AgIsoStack++ can_general_parameter_group_numbers.hpp:45";
CM_ BO_ 2566767872  "Source: AgIsoStack++ can_general_parameter_group_numbers.hpp:46";
CM_ BO_ 2566834688  "Source: AgIsoStack++ can_general_parameter_group_numbers.hpp:47. DM1 carries Active Diagnostic Trouble Codes per SAE J1939-73. Payload layout (multi-DTC, variable length): byte 0 = lamp status (MIL / Red Stop / Amber Warning / Protect, 2 bits each); byte 1 = flash status for those 4 lamps; bytes 2+ = repeating 4-byte DTC records (SPN 19-bit + FMI 5-bit + OC 7-bit + CM 1-bit). Per-DTC decoding is reader-side; this DBC documents only the frame-level definition. Public reference: CSS Electronics J1939-73 explainer (csselectronics.com). Full decode contribution welcome — see CONTRIBUTING.md.";
CM_ BO_ 2566834944  "Source: AgIsoStack++ can_general_parameter_group_numbers.hpp:48";
CM_ BO_ 2566835200  "Source: AgIsoStack++ can_general_parameter_group_numbers.hpp:49";
CM_ BO_ 2566836992  "Source: AgIsoStack++ can_general_parameter_group_numbers.hpp:50";
CM_ BO_ 2564358144  "Source: AgIsoStack++ can_general_parameter_group_numbers.hpp:51";
CM_ BO_ 2564292608  "Source: AgIsoStack++ can_general_parameter_group_numbers.hpp:52";
CM_ BO_ 2564227072  "Source: AgIsoStack++ can_general_parameter_group_numbers.hpp:53";
CM_ BO_ 2566838272  "Source: AgIsoStack++ can_general_parameter_group_numbers.hpp:54";
CM_ BO_ 2566838784  "Source: AgIsoStack++ can_general_parameter_group_numbers.hpp:55";
CM_ BO_ 2566717952  "Source: AgIsoStack++ can_general_parameter_group_numbers.hpp:56";
CM_ BO_ 2566841856  "Source: AgIsoStack++ can_general_parameter_group_numbers.hpp:57";
CM_ BO_ 2566843136  "Source: AgIsoStack++ can_general_parameter_group_numbers.hpp:58";
CM_ BO_ 2582712832  "Source: AgIsoStack++ can_general_parameter_group_numbers.hpp:59 Note: this is an NMEA 2000 marine PGN. AgIsoStack++ reuses these for GNSS/heading because NMEA 2000 and ISO 11783 share the J1939 protocol layer; they are not part of ISO 11783-7 itself.";
CM_ BO_ 2582713088  "Source: AgIsoStack++ can_general_parameter_group_numbers.hpp:60 Note: this is an NMEA 2000 marine PGN. AgIsoStack++ reuses these for GNSS/heading because NMEA 2000 and ISO 11783 share the J1939 protocol layer; they are not part of ISO 11783-7 itself.";
CM_ BO_ 2583167232  "Source: AgIsoStack++ can_general_parameter_group_numbers.hpp:61 Note: this is an NMEA 2000 marine PGN. AgIsoStack++ reuses these for GNSS/heading because NMEA 2000 and ISO 11783 share the J1939 protocol layer; they are not part of ISO 11783-7 itself.";
CM_ BO_ 2583167488  "Source: AgIsoStack++ can_general_parameter_group_numbers.hpp:62";
CM_ BO_ 2583167744  "Source: AgIsoStack++ can_general_parameter_group_numbers.hpp:63";
CM_ BO_ 2583168256  "Source: AgIsoStack++ can_general_parameter_group_numbers.hpp:64 Note: this is an NMEA 2000 marine PGN. AgIsoStack++ reuses these for GNSS/heading because NMEA 2000 and ISO 11783 share the J1939 protocol layer; they are not part of ISO 11783-7 itself.";
CM_ BO_ 2583172096  "Source: AgIsoStack++ can_general_parameter_group_numbers.hpp:65 Note: this is an NMEA 2000 marine PGN. AgIsoStack++ reuses these for GNSS/heading because NMEA 2000 and ISO 11783 share the J1939 protocol layer; they are not part of ISO 11783-7 itself.";

CM_ SG_ 2561409024 EstimatedCurvature "Source: isobus_guidance_interface.hpp GuidanceMachineInfo";
CM_ SG_ 2561409024 MachineSteeringSystemCommandExit "Per ISO 11783-7 exit reason codes";
CM_ SG_ 2561474560 CurvatureCommand "Source: isobus_guidance_interface.hpp GuidanceSystemCommand";
CM_ SG_ 2562916352 DiagnosticMessage22_RawPayload "Generic 8-byte raw payload. Signal-level decoding requires ISO 11783-X spec lookup or AgIsoStack++ parser inspection  manual enrichment via PR welcome.";
CM_ SG_ 2563178496 ExtendedTransportProtocolDataTra "Generic 8-byte raw payload. Signal-level decoding requires ISO 11783-X spec lookup or AgIsoStack++ parser inspection  manual enrichment via PR welcome.";
CM_ SG_ 2563244032 ExtendedTransportProtocolConnect "Generic 8-byte raw payload. Signal-level decoding requires ISO 11783-X spec lookup or AgIsoStack++ parser inspection  manual enrichment via PR welcome.";
CM_ SG_ 2563440640 ProcessData_RawPayload "Generic 8-byte raw payload. Signal-level decoding requires ISO 11783-X spec lookup or AgIsoStack++ parser inspection  manual enrichment via PR welcome.";
CM_ SG_ 2563506176 RequestForRepetitionRate_RawPayl "Generic 8-byte raw payload. Signal-level decoding requires ISO 11783-X spec lookup or AgIsoStack++ parser inspection  manual enrichment via PR welcome.";
CM_ SG_ 2564751360 DiagnosticMessage13_RawPayload "Generic 8-byte raw payload. Signal-level decoding requires ISO 11783-X spec lookup or AgIsoStack++ parser inspection  manual enrichment via PR welcome.";
CM_ SG_ 2565210112 VirtualTerminalToECU_RawPayload "Generic 8-byte raw payload. Signal-level decoding requires ISO 11783-X spec lookup or AgIsoStack++ parser inspection  manual enrichment via PR welcome.";
CM_ SG_ 2565275648 ECUtoVirtualTerminal_RawPayload "Generic 8-byte raw payload. Signal-level decoding requires ISO 11783-X spec lookup or AgIsoStack++ parser inspection  manual enrichment via PR welcome.";
CM_ SG_ 2565341184 Acknowledge_RawPayload "Generic 8-byte raw payload. Signal-level decoding requires ISO 11783-X spec lookup or AgIsoStack++ parser inspection  manual enrichment via PR welcome.";
CM_ SG_ 2565472256 ParameterGroupNumberRequest_RawP "Generic 8-byte raw payload. Signal-level decoding requires ISO 11783-X spec lookup or AgIsoStack++ parser inspection  manual enrichment via PR welcome.";
CM_ SG_ 2565537792 TransportProtocolDataTransfer_Ra "Generic 8-byte raw payload. Signal-level decoding requires ISO 11783-X spec lookup or AgIsoStack++ parser inspection  manual enrichment via PR welcome.";
CM_ SG_ 2565603328 TransportProtocolConnectionManag "Generic 8-byte raw payload. Signal-level decoding requires ISO 11783-X spec lookup or AgIsoStack++ parser inspection  manual enrichment via PR welcome.";
CM_ SG_ 2565734400 AddressClaim_RawPayload "Generic 8-byte raw payload. Signal-level decoding requires ISO 11783-X spec lookup or AgIsoStack++ parser inspection  manual enrichment via PR welcome.";
CM_ SG_ 2565874176 MachineSelectedSpeed "Source: isobus_speed_distance_messages.hpp MachineSelectedSpeedData";
CM_ SG_ 2565874176 MachineSelectedSpeedExitReasonCo "Source-of-selected-speed exit reason code per ISO 11783-7";
CM_ SG_ 2565874176 MachineSelectedSpeedSource "0=Wheel 1=Ground 2=Navigation 3=Blended 4=Simulated";
CM_ SG_ 2565923840 HeartbeatSequenceCounter "Increments 0..250 then wraps; per isobus_heartbeat.hpp";
CM_ SG_ 2566688000 ProductIdentification_RawPayload "Generic 8-byte raw payload. Signal-level decoding requires ISO 11783-X spec lookup or AgIsoStack++ parser inspection  manual enrichment via PR welcome.";
CM_ SG_ 2566688256 ControlFunctionFunctionalities_R "Generic 8-byte raw payload. Signal-level decoding requires ISO 11783-X spec lookup or AgIsoStack++ parser inspection  manual enrichment via PR welcome.";
CM_ SG_ 2566730240 DiagnosticProtocolIdentification "Generic 8-byte raw payload. Signal-level decoding requires ISO 11783-X spec lookup or AgIsoStack++ parser inspection  manual enrichment via PR welcome.";
CM_ SG_ 2566734592 MachineSelectedSpeedCommand_RawP "Generic 8-byte raw payload. Signal-level decoding requires ISO 11783-X spec lookup or AgIsoStack++ parser inspection  manual enrichment via PR welcome.";
CM_ SG_ 2566786304 WorkingSetMaster_RawPayload "Generic 8-byte raw payload. Signal-level decoding requires ISO 11783-X spec lookup or AgIsoStack++ parser inspection  manual enrichment via PR welcome.";
CM_ SG_ 2566786816 LanguageCode_Byte0 "ASCII char 1 of ISO 639-1 language code, e.g. 'e' for en";
CM_ SG_ 2566786816 LanguageCode_Byte1 "ASCII char 2";
CM_ SG_ 2566786816 NumberFormat "Decimal separator + grouping convention";
CM_ SG_ 2566786816 DateFormat "0=ddmmyyyy 1=ddyyyymm 2=mmyyyydd 3=mmddyyyy 4=yyyymmdd 5=yyyyddmm";
CM_ SG_ 2566786816 TimeFormat "0=24h 1=12h";
CM_ SG_ 2566786816 DistanceUnits "0=metric 1=imperial-US 2=imperial-UK 3=reserved";
CM_ SG_ 2566801152 MaintainPower_MaxTimeFromOff "MaintainPower request  maximum time for ECU power-down";
CM_ SG_ 2566801408 WheelBasedMachineSpeed "Source: isobus_speed_distance_messages.hpp WheelBasedMachineSpeedData";
CM_ SG_ 2566801408 WheelBasedMachineDistance "Source: isobus_speed_distance_messages.hpp";
CM_ SG_ 2566801408 MaximumTimeOfTractorPowerOk "Source: isobus_speed_distance_messages.hpp";
CM_ SG_ 2566801408 OperatorDirectionReversed "0=NotReversed 1=Reversed 2=Error 3=NotAvailable";
CM_ SG_ 2566801408 StartStopState "0=Stop 1=Start 2=Error 3=NotAvailable";
CM_ SG_ 2566801408 KeySwitchState "0=Off 1=NotOff 2=Error 3=NotAvailable";
CM_ SG_ 2566801408 MachineDirection "0=Reverse 1=Forward 2=Error 3=NotAvailable";
CM_ SG_ 2566801664 GroundBasedMachineSpeed "Source: isobus_speed_distance_messages.hpp GroundBasedSpeedAndDistance";
CM_ SG_ 2566801664 GroundBasedMachineDistance "Source: isobus_speed_distance_messages.hpp";
CM_ SG_ 2566801664 MachineDirection "0=Reverse 1=Forward 2=Error 3=NotAvailable";
CM_ SG_ 2566767872 ECUIdentificationInformation_Raw "Generic 8-byte raw payload. Signal-level decoding requires ISO 11783-X spec lookup or AgIsoStack++ parser inspection  manual enrichment via PR welcome.";
CM_ SG_ 2566834688 DiagnosticMessage1_RawPayload "Generic 8-byte raw payload. Signal-level decoding requires ISO 11783-X spec lookup or AgIsoStack++ parser inspection  manual enrichment via PR welcome.";
CM_ SG_ 2566834944 DiagnosticMessage2_RawPayload "Generic 8-byte raw payload. Signal-level decoding requires ISO 11783-X spec lookup or AgIsoStack++ parser inspection  manual enrichment via PR welcome.";
CM_ SG_ 2566835200 DiagnosticMessage3_RawPayload "Generic 8-byte raw payload. Signal-level decoding requires ISO 11783-X spec lookup or AgIsoStack++ parser inspection  manual enrichment via PR welcome.";
CM_ SG_ 2566836992 DiagnosticMessage11_RawPayload "Generic 8-byte raw payload. Signal-level decoding requires ISO 11783-X spec lookup or AgIsoStack++ parser inspection  manual enrichment via PR welcome.";
CM_ SG_ 2564358144 DiagnosticMessage14_RawPayload "Generic 8-byte raw payload. Signal-level decoding requires ISO 11783-X spec lookup or AgIsoStack++ parser inspection  manual enrichment via PR welcome.";
CM_ SG_ 2564292608 DiagnosticMessage15_RawPayload "Generic 8-byte raw payload. Signal-level decoding requires ISO 11783-X spec lookup or AgIsoStack++ parser inspection  manual enrichment via PR welcome.";
CM_ SG_ 2564227072 DiagnosticMessage16_RawPayload "Generic 8-byte raw payload. Signal-level decoding requires ISO 11783-X spec lookup or AgIsoStack++ parser inspection  manual enrichment via PR welcome.";
CM_ SG_ 2566838272 CommandedAddress_RawPayload "Generic 8-byte raw payload. Signal-level decoding requires ISO 11783-X spec lookup or AgIsoStack++ parser inspection  manual enrichment via PR welcome.";
CM_ SG_ 2566838784 SoftwareIdentification_RawPayloa "Generic 8-byte raw payload. Signal-level decoding requires ISO 11783-X spec lookup or AgIsoStack++ parser inspection  manual enrichment via PR welcome.";
CM_ SG_ 2566717952 AllImplementsStopOperationsSwitc "Generic 8-byte raw payload. Signal-level decoding requires ISO 11783-X spec lookup or AgIsoStack++ parser inspection  manual enrichment via PR welcome.";
CM_ SG_ 2566843136 ComponentIdentification_RawPaylo "Generic 8-byte raw payload. Signal-level decoding requires ISO 11783-X spec lookup or AgIsoStack++ parser inspection  manual enrichment via PR welcome.";
CM_ SG_ 2582712832 VesselHeading_RawPayload "Generic 8-byte raw payload. Signal-level decoding requires ISO 11783-X spec lookup or AgIsoStack++ parser inspection  manual enrichment via PR welcome.";
CM_ SG_ 2582713088 RateOfTurn_RawPayload "Generic 8-byte raw payload. Signal-level decoding requires ISO 11783-X spec lookup or AgIsoStack++ parser inspection  manual enrichment via PR welcome.";
CM_ SG_ 2583167232 PositionRapidUpdate_RawPayload "Generic 8-byte raw payload. Signal-level decoding requires ISO 11783-X spec lookup or AgIsoStack++ parser inspection  manual enrichment via PR welcome.";
CM_ SG_ 2583167488 CourseOverGroundSpeedOverGroundR "Generic 8-byte raw payload. Signal-level decoding requires ISO 11783-X spec lookup or AgIsoStack++ parser inspection  manual enrichment via PR welcome.";
CM_ SG_ 2583167744 PositionDeltaHighPrecisionRapidU "Generic 8-byte raw payload. Signal-level decoding requires ISO 11783-X spec lookup or AgIsoStack++ parser inspection  manual enrichment via PR welcome.";
CM_ SG_ 2583168256 GNSSPositionData_RawPayload "Generic 8-byte raw payload. Signal-level decoding requires ISO 11783-X spec lookup or AgIsoStack++ parser inspection  manual enrichment via PR welcome.";
CM_ SG_ 2583172096 Datum_RawPayload "Generic 8-byte raw payload. Signal-level decoding requires ISO 11783-X spec lookup or AgIsoStack++ parser inspection  manual enrichment via PR welcome.";

BA_DEF_ BO_ "SystemMessageLongSymbol" STRING;
BA_DEF_ SG_ "GenSigStartValue" FLOAT 0 100000000000;
BA_DEF_ SG_ "SystemSignalLongSymbol" STRING;

BA_ "SystemMessageLongSymbol" BO_ 2561474560 "AgriculturalGuidanceSystemCommand";
BA_ "SystemMessageLongSymbol" BO_ 2563178496 "ExtendedTransportProtocolDataTransfer";
BA_ "SystemMessageLongSymbol" BO_ 2563244032 "ExtendedTransportProtocolConnectionManagement";
BA_ "SystemMessageLongSymbol" BO_ 2565603328 "TransportProtocolConnectionManagement";
BA_ "SystemMessageLongSymbol" BO_ 2566717952 "AllImplementsStopOperationsSwitchState";
BA_ "SystemMessageLongSymbol" BO_ 2583167488 "CourseOverGroundSpeedOverGroundRapidUpdate";
BA_ "SystemMessageLongSymbol" BO_ 2583167744 "PositionDeltaHighPrecisionRapidUpdate";

BA_ "GenSigStartValue" SG_ 2147527680 EstimatedCurvature 32128;
BA_ "SystemSignalLongSymbol" SG_ 2147527680 MachineSteeringSystemReadinessSt "MachineSteeringSystemReadinessState";
BA_ "SystemSignalLongSymbol" SG_ 2147527680 MachineSteeringSystemCommandExit "MachineSteeringSystemCommandExitReasonCode";
BA_ "GenSigStartValue" SG_ 2147527936 CurvatureCommand 32128;
BA_ "SystemSignalLongSymbol" SG_ 2147534592 ExtendedTransportProtocolDataTra "ExtendedTransportProtocolDataTransfer_RawPayload";
BA_ "SystemSignalLongSymbol" SG_ 2147534848 ExtendedTransportProtocolConnect "ExtendedTransportProtocolConnectionManagement_RawPayload";
BA_ "SystemSignalLongSymbol" SG_ 2147535872 RequestForRepetitionRate_RawPayl "RequestForRepetitionRate_RawPayload";
BA_ "SystemSignalLongSymbol" SG_ 2147543552 ParameterGroupNumberRequest_RawP "ParameterGroupNumberRequest_RawPayload";
BA_ "SystemSignalLongSymbol" SG_ 2147543808 TransportProtocolDataTransfer_Ra "TransportProtocolDataTransfer_RawPayload";
BA_ "SystemSignalLongSymbol" SG_ 2147544064 TransportProtocolConnectionManag "TransportProtocolConnectionManagement_RawPayload";
BA_ "SystemSignalLongSymbol" SG_ 2147545122 MachineSelectedSpeedExitReasonCo "MachineSelectedSpeedExitReasonCode";
BA_ "SystemSignalLongSymbol" SG_ 2147548302 ControlFunctionFunctionalities_R "ControlFunctionFunctionalities_RawPayload";
BA_ "SystemSignalLongSymbol" SG_ 2147548466 DiagnosticProtocolIdentification "DiagnosticProtocolIdentification_RawPayload";
BA_ "SystemSignalLongSymbol" SG_ 2147548483 MachineSelectedSpeedCommand_RawP "MachineSelectedSpeedCommand_RawPayload";
BA_ "SystemSignalLongSymbol" SG_ 2147548743 MaintainPower_ImplementInWorkSta "MaintainPower_ImplementInWorkState";
BA_ "SystemSignalLongSymbol" SG_ 2147548743 MaintainPower_ImplementReadyToWo "MaintainPower_ImplementReadyToWorkState";
BA_ "SystemSignalLongSymbol" SG_ 2147548613 ECUIdentificationInformation_Raw "ECUIdentificationInformation_RawPayload";
BA_ "SystemSignalLongSymbol" SG_ 2147548890 SoftwareIdentification_RawPayloa "SoftwareIdentification_RawPayload";
BA_ "SystemSignalLongSymbol" SG_ 2147548418 AllImplementsStopOperationsSwitc "AllImplementsStopOperationsSwitchState_RawPayload";
BA_ "GenSigStartValue" SG_ 2147548902 LocalMinuteOffset 125;
BA_ "GenSigStartValue" SG_ 2147548902 LocalHourOffset 125;
BA_ "SystemSignalLongSymbol" SG_ 2147548907 ComponentIdentification_RawPaylo "ComponentIdentification_RawPayload";
BA_ "SystemSignalLongSymbol" SG_ 2147612674 CourseOverGroundSpeedOverGroundR "CourseOverGroundSpeedOverGroundRapidUpdate_RawPayload";
BA_ "SystemSignalLongSymbol" SG_ 2147612675 PositionDeltaHighPrecisionRapidU "PositionDeltaHighPrecisionRapidUpdate_RawPayload";

VAL_ 2561409024 MechanicalSystemLockoutState 0 "NotActive" 1 "Active" 2 "Error" 3 "NotAvailable";
VAL_ 2561409024 MachineSteeringSystemReadinessSt 0 "NotReady" 1 "Ready" 2 "Error" 3 "NotAvailable";
VAL_ 2561409024 GuidanceLimitStatus 0 "NotLimited" 1 "OperatorLimited" 2 "LimitedHigh" 3 "LimitedLow";
VAL_ 2561409024 GuidanceRequestStatus 0 "RequiredNoSteer" 1 "Required" 2 "Error" 3 "NotAvailable";
VAL_ 2561474560 CurvatureCommandStatus 0 "IntendedNotSteering" 1 "IntendedSteering" 2 "Error" 3 "NotAvailable";
VAL_ 2565874176 MachineSelectedSpeedSource 0 "Wheel" 1 "Ground" 2 "Navigation" 3 "Blended" 4 "Simulated";
VAL_ 2565874176 MachineDirection 0 "Reverse" 1 "Forward" 2 "Error" 3 "NotAvailable";
VAL_ 2566801152 MaintainPower_MaxTimeFromOff 0 "DoNotMaintain" 1 "Maintain2Sec" 2 "MaintainExt" 3 "NotAvailable";
VAL_ 2566801152 MaintainPower_KeySwitchState 0 "Off" 1 "NotOff" 2 "Error" 3 "NotAvailable";
VAL_ 2566801152 MaintainPower_ImplementInWorkSta 0 "NotInWork" 1 "InWork" 2 "Error" 3 "NotAvailable";
VAL_ 2566801152 MaintainPower_ImplementReadyToWo 0 "NotReady" 1 "Ready" 2 "Error" 3 "NotAvailable";
VAL_ 2566801408 OperatorDirectionReversed 0 "NotReversed" 1 "Reversed" 2 "Error" 3 "NotAvailable";
VAL_ 2566801408 StartStopState 0 "Stop" 1 "Start" 2 "Error" 3 "NotAvailable";
VAL_ 2566801408 KeySwitchState 0 "Off" 1 "NotOff" 2 "Error" 3 "NotAvailable";
VAL_ 2566801408 MachineDirection 0 "Reverse" 1 "Forward" 2 "Error" 3 "NotAvailable";
VAL_ 2566801664 MachineDirection 0 "Reverse" 1 "Forward" 2 "Error" 3 "NotAvailable";
